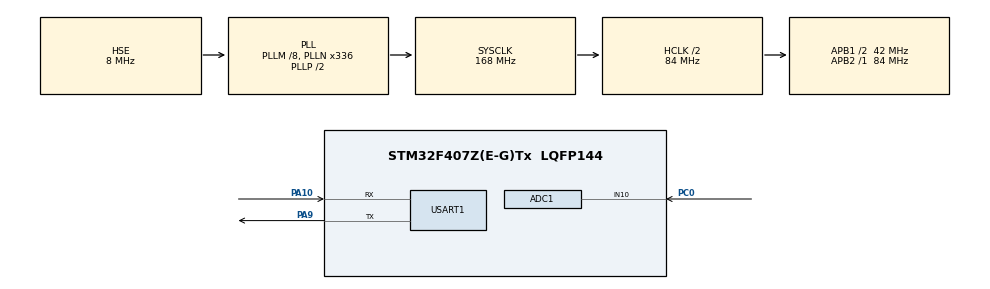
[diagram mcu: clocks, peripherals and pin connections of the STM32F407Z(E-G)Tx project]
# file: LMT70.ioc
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ADC1.Channel-0\#ChannelRegularConversion=ADC_CHANNEL_10
ADC1.ContinuousConvMode=ENABLE
ADC1.DMAContinuousRequests=ENABLE
ADC1.NbrOfConversionFlag=1
ADC1.Rank-0\#ChannelRegularConversion=1
ADC1.SamplingTime-0\#ChannelRegularConversion=ADC_SAMPLETIME_3CYCLES
ADC1.master=1
Dma.ADC1.0.Direction=DMA_PERIPH_TO_MEMORY
Dma.ADC1.0.FIFOMode=DMA_FIFOMODE_DISABLE
Dma.ADC1.0.Instance=DMA2_Stream0
Dma.ADC1.0.MemDataAlignment=DMA_MDATAALIGN_HALFWORD
Dma.ADC1.0.MemInc=DMA_MINC_ENABLE
Dma.ADC1.0.Mode=DMA_NORMAL
Dma.ADC1.0.PeriphDataAlignment=DMA_PDATAALIGN_HALFWORD
Dma.ADC1.0.PeriphInc=DMA_PINC_DISABLE
Dma.ADC1.0.Priority=DMA_PRIORITY_LOW
Dma.Request0=ADC1
Mcu.Family=STM32F4
Mcu.Name=STM32F407Z(E-G)Tx
Mcu.Package=LQFP144
NVIC.DMA2_Stream0_IRQn=true\:0\:0\:false\:false\:true\:false\:true
NVIC.PriorityGroup=NVIC_PRIORITYGROUP_4
PA10.Mode=Asynchronous
PA10.Signal=USART1_RX
PA9.Mode=Asynchronous
PA9.Signal=USART1_TX
PC0.Signal=ADCx_IN10
PH0-OSC_IN.Mode=HSE-External-Oscillator
PH0-OSC_IN.Signal=RCC_OSC_IN
PH1-OSC_OUT.Mode=HSE-External-Oscillator
PH1-OSC_OUT.Signal=RCC_OSC_OUT
ProjectManager.HeapSize=0x200
ProjectManager.StackSize=0x400
ProjectManager.TargetToolchain=MDK-ARM V5.27
RCC.48MHZClocksFreq_Value=84000000
RCC.AHBCLKDivider=RCC_SYSCLK_DIV2
RCC.AHBFreq_Value=84000000
RCC.APB1CLKDivider=RCC_HCLK_DIV2
RCC.APB1Freq_Value=42000000
RCC.APB1TimFreq_Value=84000000
RCC.APB2Freq_Value=84000000
RCC.APB2TimFreq_Value=84000000
RCC.CortexFreq_Value=84000000
RCC.HCLKFreq_Value=84000000
RCC.HSE_VALUE=8000000
RCC.HSI_VALUE=16000000
RCC.LSE_VALUE=32768
RCC.PLLM=8
RCC.PLLN=336
RCC.PLLSourceVirtual=RCC_PLLSOURCE_HSE
RCC.SYSCLKFreq_VALUE=168000000
RCC.SYSCLKSource=RCC_SYSCLKSOURCE_PLLCLK
RCC.VCOOutputFreq_Value=336000000
SH.ADCx_IN10.0=ADC1_IN10,IN10
USART1.VirtualMode=VM_ASYNC
board=custom

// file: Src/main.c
/* USER CODE BEGIN Header */
/**
  ******************************************************************************
  * @file           : main.c
  * @brief          : Main program body
  ******************************************************************************
  * @attention
  *
  * <h2><center>&copy; Copyright (c) 2020 STMicroelectronics.
  * All rights reserved.</center></h2>
  *
  * This software component is licensed by ST under BSD 3-Clause license,
  * the "License"; You may not use this file except in compliance with the
  * License. You may obtain a copy of the License at:
  *                        opensource.org/licenses/BSD-3-Clause
  *
  ******************************************************************************
  */
/* USER CODE END Header */

#include "main.h"
#include "adc.h"
#include "dma.h"
#include "usart.h"
#include "gpio.h"

/* USER CODE BEGIN Includes */
#include "LMT70.h"
/* USER CODE END Includes */

void SystemClock_Config(void);

int main(void)
{

  /* MCU Configuration--------------------------------------------------------*/

  /* Reset of all peripherals, Initializes the Flash interface and the Systick. */
  HAL_Init();

  /* Configure the system clock */
  SystemClock_Config();

  /* Initialize all configured peripherals */
  MX_GPIO_Init();
  MX_DMA_Init();
  MX_ADC1_Init();
  MX_USART1_UART_Init();
  /* USER CODE BEGIN 2 */
	HAL_ADC_Start_DMA(&hadc1, (uint32_t*)&ADC_ConvertedValue[0], 20);
  /* USER CODE END 2 */

  /* Infinite loop */
  /* USER CODE BEGIN WHILE */
  while (1)
  {
		Temperature=Get_LMT70_Temperature();
		printf("Temperature=%.2lf\r\n",Temperature);
		HAL_Delay(200);
    /* USER CODE END WHILE */

  }
}

void SystemClock_Config(void)
{
  RCC_OscInitTypeDef RCC_OscInitStruct = {0};
  RCC_ClkInitTypeDef RCC_ClkInitStruct = {0};

  /** Configure the main internal regulator output voltage
  */
  __HAL_RCC_PWR_CLK_ENABLE();
  __HAL_PWR_VOLTAGESCALING_CONFIG(PWR_REGULATOR_VOLTAGE_SCALE1);
  /** Initializes the CPU, AHB and APB busses clocks
  */
  RCC_OscInitStruct.OscillatorType = RCC_OSCILLATORTYPE_HSE;
  RCC_OscInitStruct.HSEState = RCC_HSE_ON;
  RCC_OscInitStruct.PLL.PLLState = RCC_PLL_ON;
  RCC_OscInitStruct.PLL.PLLSource = RCC_PLLSOURCE_HSE;
  RCC_OscInitStruct.PLL.PLLM = 8;
  RCC_OscInitStruct.PLL.PLLN = 336;
  RCC_OscInitStruct.PLL.PLLP = RCC_PLLP_DIV2;
  RCC_OscInitStruct.PLL.PLLQ = 4;
  if (HAL_RCC_OscConfig(&RCC_OscInitStruct) != HAL_OK)
  {
    Error_Handler();
  }
  /** Initializes the CPU, AHB and APB busses clocks
  */
  RCC_ClkInitStruct.ClockType = RCC_CLOCKTYPE_HCLK|RCC_CLOCKTYPE_SYSCLK
                              |RCC_CLOCKTYPE_PCLK1|RCC_CLOCKTYPE_PCLK2;
  RCC_ClkInitStruct.SYSCLKSource = RCC_SYSCLKSOURCE_PLLCLK;
  RCC_ClkInitStruct.AHBCLKDivider = RCC_SYSCLK_DIV2;
  RCC_ClkInitStruct.APB1CLKDivider = RCC_HCLK_DIV2;
  RCC_ClkInitStruct.APB2CLKDivider = RCC_HCLK_DIV1;

  if (HAL_RCC_ClockConfig(&RCC_ClkInitStruct, FLASH_LATENCY_2) != HAL_OK)
  {
    Error_Handler();
  }
}

void Error_Handler(void)
{
}

/************************ (C) COPYRIGHT STMicroelectronics *****END OF FILE****/
